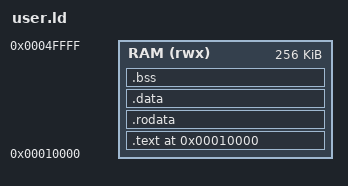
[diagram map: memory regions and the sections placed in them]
/* User program linker script */
OUTPUT_FORMAT("elf64-littleriscv", "elf64-littleriscv", "elf64-littleriscv")
OUTPUT_ARCH(riscv)
ENTRY(_start)

MEMORY
{
    RAM (rwx) : ORIGIN = 0x10000, LENGTH = 256K
}

SECTIONS
{
    . = 0x10000;
    
    .text : {
        *(.text.start)
        *(.text .text.*)
    } > RAM
    
    .rodata : {
        *(.rodata .rodata.*)
    } > RAM
    
    .data : {
        *(.data .data.*)
    } > RAM
    
    .bss : {
        *(.bss .bss.*)
        *(COMMON)
    } > RAM
    
    /DISCARD/ : {
        *(.comment)
        *(.note*)
        *(.eh_frame*)
    }
}
